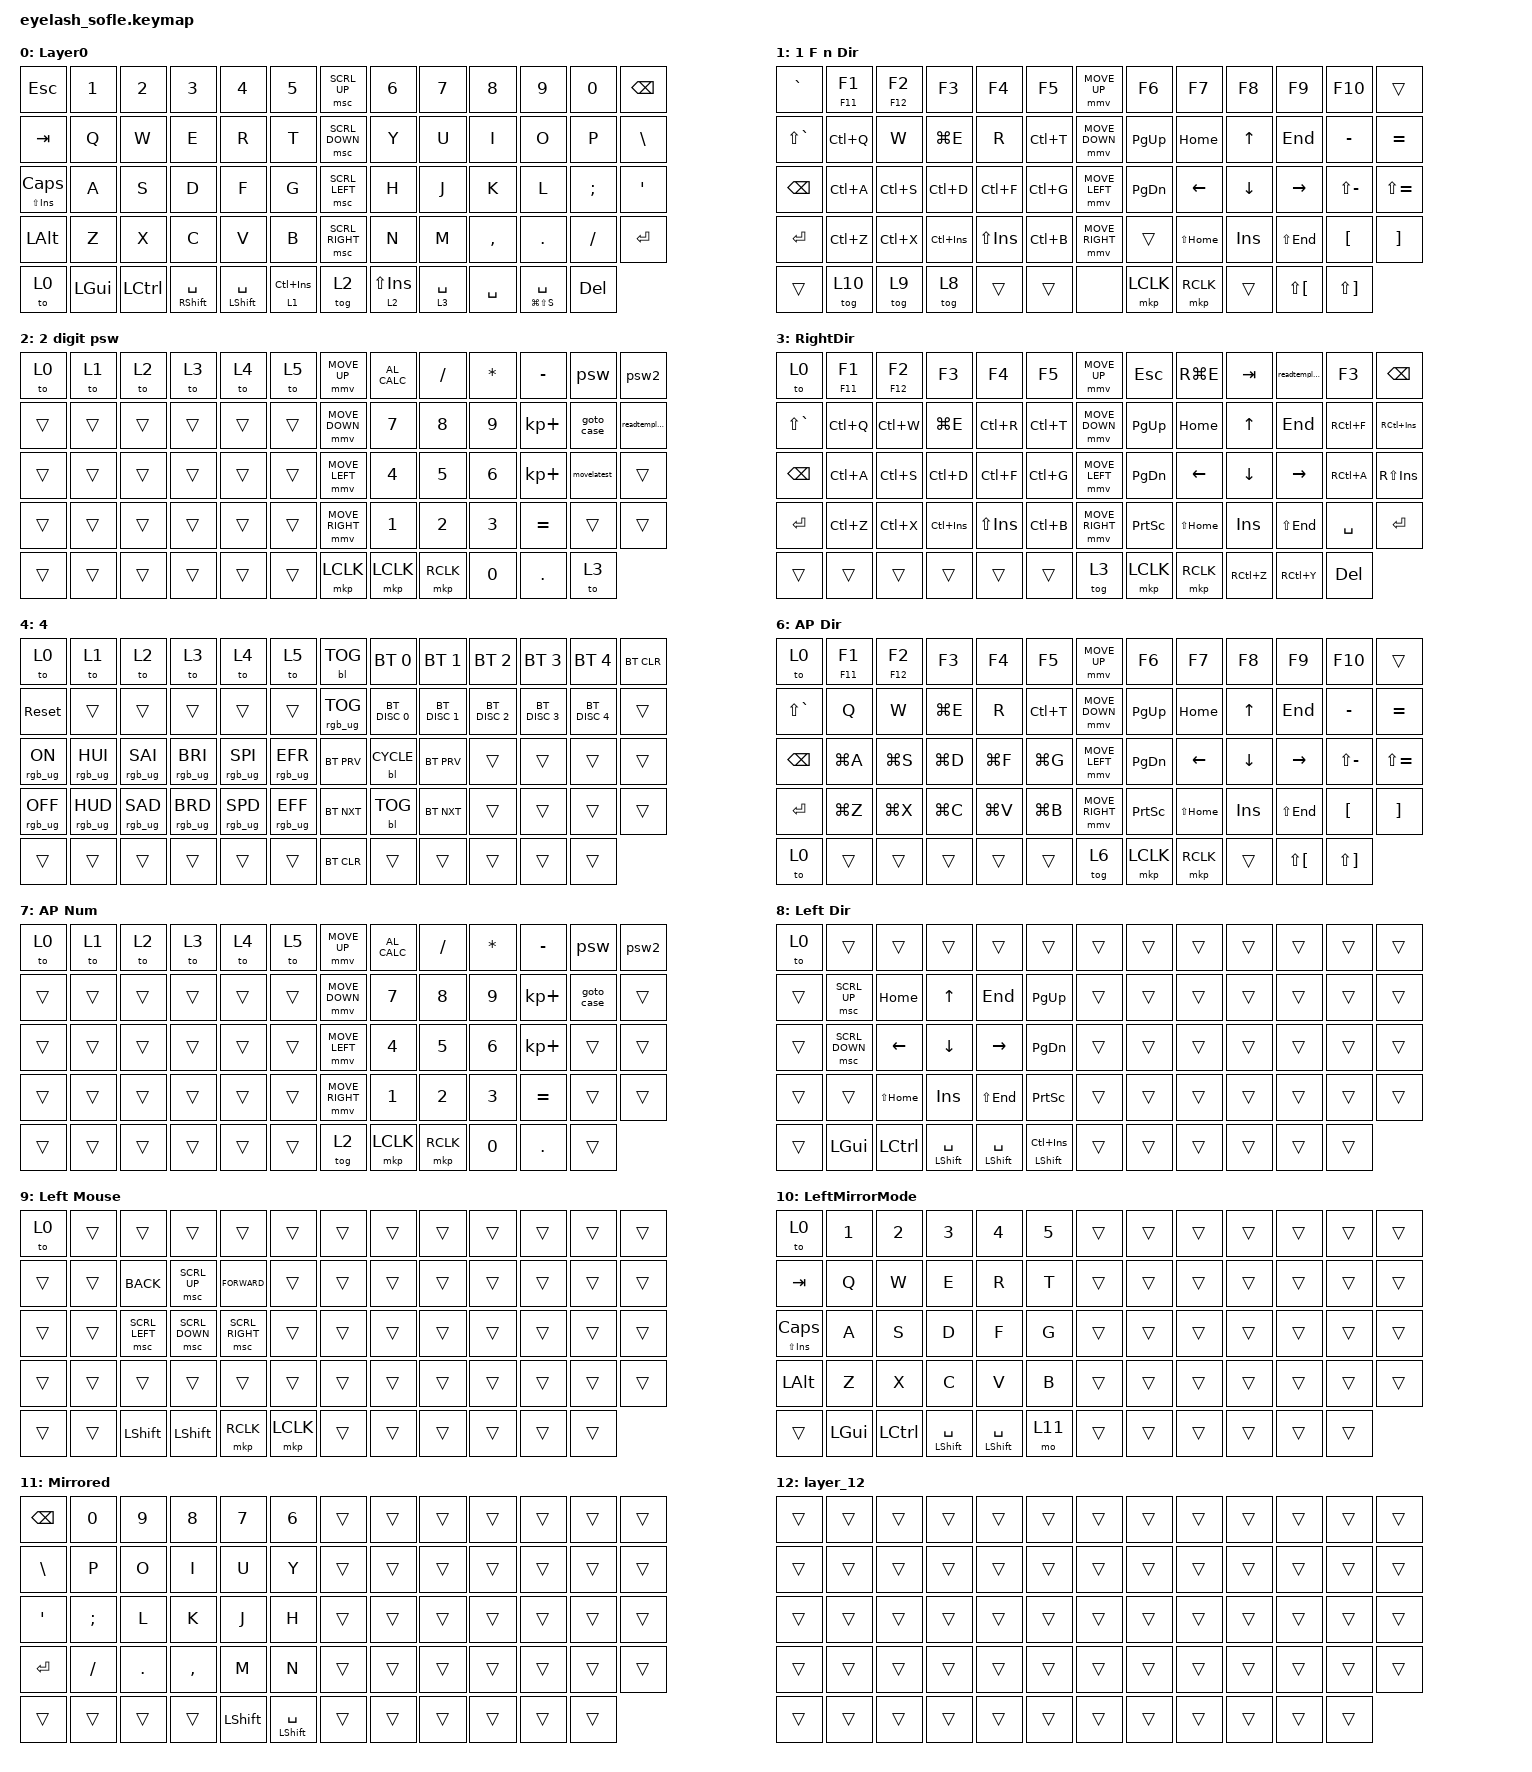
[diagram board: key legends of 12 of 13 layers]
#include <dt-bindings/zmk/mouse.h>
#include <input/processors.dtsi>
#include <behaviors.dtsi>
#include <dt-bindings/zmk/backlight.h>
#include <dt-bindings/zmk/bt.h>
#include <dt-bindings/zmk/keys.h>
#include <dt-bindings/zmk/pointing.h>
#include <dt-bindings/zmk/rgb.h>

/*

   &mmv_input_listener {
       input-processors = <&zip_xy_scaler 2 1>;
   };

   &msc_input_listener {
       input-processors = <&zip_xy_scaler 2 1>;
   };

 */

#define ZMK_MOUSE_DEFAULT_MOVE_VAL 1200  // 600
#define ZMK_MOUSE_DEFAULT_SCRL_VAL 20    // 10

/ {
    behaviors {
        mmv {
            acceleration-exponent = <1>;      // 1
            time-to-max-speed-ms = <900>;    // 40
            delay-ms = <0>;                   // 0
        };

        msc {
            acceleration-exponent = <1>;      // 0
            time-to-max-speed-ms = <400>;      // 500
            delay-ms = <0>;                   //   10
        };
    };

    scroll_encoder: scroll_encoder {
        compatible = "zmk,behavior-sensor-rotate";
        #sensor-binding-cells = <0>;
        bindings = <&kp K_VOLUME_DOWN>, <&kp K_VOLUME_UP>;

        tap-ms = <30>;
        label = "croll_LeftRight";
    };

    rotete_var: rotete_var {
        compatible = "zmk,behavior-sensor-rotate-var";
        label = "ROTETE_VAR";
        #sensor-binding-cells = <2>;
        bindings = <&msc>, <&msc>;

        tap-ms = <30>;
    };

    rotate_up_Down: rotate_up_Down {
        compatible = "zmk,behavior-sensor-rotate";
        label = "ROTATE_UP_DOWN";
        #sensor-binding-cells = <0>;
        bindings = <&msc SCRL_UP>, <&msc SCRL_DOWN>;
    };

    macros {
        goto_case: goto_case {
            compatible = "zmk,behavior-macro";
            #binding-cells = <0>;
            bindings =
                <&macro_press>,
                <&kp LEFT_WIN>,
                <&macro_tap>,
                <&kp R>,
                <&macro_wait_time 80>,
                <&macro_release>,
                <&kp LEFT_WIN>,
                <&macro_tap>,
                <&macro_wait_time 20>,
                <&none &none>,
                <&macro_tap_time 15>,
                <&kp C &kp A &kp S &kp E &kp UNDER &kp G &kp O &kp T &kp O &kp SPACE &kp LS(INSERT) &kp ENTER>;

            label = "GOTO_CASE";
        };

        psw: psw {
            compatible = "zmk,behavior-macro";
            #binding-cells = <0>;
            bindings =
                <&macro_wait_time 30>,
                <&kp LS(A) &kp G &kp A &kp I &kp N &kp A &kp N &kp D &kp LS(A) &kp G &kp A &kp I &kp N &kp I &kp T &kp G &kp O &kp T &kp C &kp H &kp A &kp N &kp G &kp E &kp D &kp N1 &kp AT>;

            label = "PSW";
        };

        psw2: psw2 {
            compatible = "zmk,behavior-macro";
            #binding-cells = <0>;
            bindings =
                <&macro_wait_time 30>,
                <&none &kp LS(A) &kp D &kp M &kp I &kp N &kp I &kp S &kp T &kp R &kp A &kp T &kp O &kp R &kp N1 &kp AT>;

            label = "PSW2";
        };

        movelatest: movelatest {
            compatible = "zmk,behavior-macro";
            #binding-cells = <0>;
            bindings =
                <&macro_press>,
                <&kp LEFT_WIN>,
                <&macro_tap>,
                <&kp R>,
                <&macro_wait_time 80>,
                <&macro_release>,
                <&kp LEFT_WIN>,
                <&macro_tap>,
                <&macro_wait_time 20>,
                <&none &none>,
                <&macro_tap_time 15>,
                <&kp C &kp A &kp S &kp E &kp UNDER &kp M &kp O &kp V &kp E &kp L &kp A &kp T &kp E &kp S &kp T &kp DOT &kp B &kp A &kp T &kp SPACE &kp LS(INSERT)>;

            label = "MOVELATEST";
        };

        readtemplate: readtemplate {
            compatible = "zmk,behavior-macro";
            #binding-cells = <0>;
            bindings =
                <&macro_press>,
                <&kp LEFT_WIN>,
                <&macro_tap>,
                <&kp R>,
                <&macro_wait_time 80>,
                <&macro_release>,
                <&kp LEFT_WIN>,
                <&macro_tap>,
                <&macro_wait_time 30>,
                <&none &none>,
                <&macro_tap_time 20>,
                <&kp R &kp SPACE &kp N3 &kp DELETE &kp ENTER>;

            label = "READTEMPLATE";
        };
    };

    keymap {
        compatible = "zmk,keymap";

        Layer0 {
            bindings = <
&kp ESC           &kp N1        &kp N2            &kp N3           &kp N4                &kp N5           &msc SCRL_UP     &kp N6         &kp N7       &kp N8     &kp N9               &kp N0      &kp BACKSPACE
&kp TAB           &kp Q         &kp W             &kp E            &kp R                 &kp T            &msc SCRL_DOWN   &kp Y          &kp U        &kp I      &kp O                &kp P       &kp BSLH
&mt LS(INS) CAPS  &kp A         &kp S             &kp D            &kp F                 &kp G            &msc SCRL_LEFT   &kp H          &kp J        &kp K      &kp L                &kp SEMI    &kp APOS
&kp LEFT_ALT      &kp Z         &kp X             &kp C            &kp V                 &kp B            &msc SCRL_RIGHT  &kp N          &kp M        &kp COMMA  &kp DOT              &kp FSLH    &kp ENTER
&to 0             &kp LEFT_GUI  &kp LEFT_CONTROL  &mt RSHFT SPACE  &mt LEFT_SHIFT SPACE  &lt 1 LC(INS)    &tog 2           &lt 2 LS(INS)  &lt 3 SPACE  &kp SPACE  &mt LG(LS(S)) SPACE  &kp DELETE
            >;

            sensor-bindings = <&inc_dec_kp C_VOLUME_UP C_VOLUME_DOWN>;
            display-name = "Layer0";
        };

        layer_1 {
            bindings = <
&kp GRAVE      &mt F11 F1  &mt F12 F2  &kp F3       &kp F4       &kp F5       &mmv MOVE_UP     &kp F6         &kp F7        &kp F8    &kp F9                &kp F10                &trans
&kp LS(GRAVE)  &kp LC(Q)   &kp W       &kp LG(E)    &kp R        &kp LC(T)    &mmv MOVE_DOWN   &kp PAGE_UP    &kp HOME      &kp UP    &kp END               &kp MINUS              &kp EQUAL
&kp BSPC       &kp LC(A)   &kp LC(S)   &kp LC(D)    &kp LC(F)    &kp LC(G)    &mmv MOVE_LEFT   &kp PAGE_DOWN  &kp LEFT      &kp DOWN  &kp RIGHT             &kp LS(MINUS)          &kp LS(EQUAL)
&kp ENTER      &kp LC(Z)   &kp LC(X)   &kp LC(INS)  &kp LS(INS)  &kp LC(B)    &mmv MOVE_RIGHT  &trans         &kp LS(HOME)  &kp INS   &kp LS(END)           &kp LEFT_BRACKET       &kp RIGHT_BRACKET
&trans         &tog 10     &tog 9      &tog 8       &trans       &trans       &none            &mkp LCLK      &mkp RCLK     &trans    &kp LS(LEFT_BRACKET)  &kp LS(RIGHT_BRACKET)
            >;

            label = "1 F n Dir ";
            sensor-bindings = <&inc_dec_kp C_BRIGHTNESS_INC C_BRIGHTNESS_DEC>;
        };

        layer_2 {
            bindings = <
&to 0   &to 1   &to 2   &to 3   &to 4   &to 5     &mmv MOVE_UP     &kp C_AL_CALC  &kp FSLH   &kp ASTRK  &kp MINUS    &psw         &psw2
&trans  &trans  &trans  &trans  &trans  &trans    &mmv MOVE_DOWN   &kp N7         &kp N8     &kp N9     &kp KP_PLUS  &goto_case   &readtemplate
&trans  &trans  &trans  &trans  &trans  &trans    &mmv MOVE_LEFT   &kp N4         &kp N5     &kp N6     &kp KP_PLUS  &movelatest  &trans
&trans  &trans  &trans  &trans  &trans  &trans    &mmv MOVE_RIGHT  &kp N1         &kp N2     &kp N3     &kp EQUAL    &trans       &trans
&trans  &trans  &trans  &trans  &trans  &trans    &mkp LCLK        &mkp LCLK      &mkp RCLK  &kp N0     &kp PERIOD   &to 3
            >;

            label = "2 digit psw";
        };

        layer_3 {
            bindings = <
&to 0          &mt F11 F1  &mt F12 F2  &kp F3       &kp F4       &kp F5       &mmv MOVE_UP     &kp ESCAPE       &kp RG(E)     &kp TAB    &readtemplate  &kp F3      &kp BACKSPACE
&kp LS(GRAVE)  &kp LC(Q)   &kp LC(W)   &kp LG(E)    &kp LC(R)    &kp LC(T)    &mmv MOVE_DOWN   &kp PAGE_UP      &kp HOME      &kp UP     &kp END        &kp RC(F)   &kp RC(INSERT)
&kp BSPC       &kp LC(A)   &kp LC(S)   &kp LC(D)    &kp LC(F)    &kp LC(G)    &mmv MOVE_LEFT   &kp PAGE_DOWN    &kp LEFT      &kp DOWN   &kp RIGHT      &kp RC(A)   &kp RS(INSERT)
&kp ENTER      &kp LC(Z)   &kp LC(X)   &kp LC(INS)  &kp LS(INS)  &kp LC(B)    &mmv MOVE_RIGHT  &kp PRINTSCREEN  &kp LS(HOME)  &kp INS    &kp LS(END)    &kp SPACE   &kp ENTER
&trans         &trans      &trans      &trans       &trans       &trans       &tog 3           &mkp LCLK        &mkp RCLK     &kp RC(Z)  &kp RC(Y)      &kp DELETE
            >;

            label = "RightDir";
        };

        control_4 {
            bindings = <
&to 0            &to 1            &to 2            &to 3            &to 4            &to 5              &bl BL_TOG       &bt BT_SEL 0   &bt BT_SEL 1   &bt BT_SEL 2   &bt BT_SEL 3   &bt BT_SEL 4   &bt BT_CLR
&sys_reset       &trans           &trans           &trans           &trans           &trans             &rgb_ug RGB_TOG  &bt BT_DISC 0  &bt BT_DISC 1  &bt BT_DISC 2  &bt BT_DISC 3  &bt BT_DISC 4  &trans
&rgb_ug RGB_ON   &rgb_ug RGB_HUI  &rgb_ug RGB_SAI  &rgb_ug RGB_BRI  &rgb_ug RGB_SPI  &rgb_ug RGB_EFR    &bt BT_PRV       &bl BL_CYCLE   &bt BT_PRV     &trans         &trans         &trans         &trans
&rgb_ug RGB_OFF  &rgb_ug RGB_HUD  &rgb_ug RGB_SAD  &rgb_ug RGB_BRD  &rgb_ug RGB_SPD  &rgb_ug RGB_EFF    &bt BT_NXT       &bl BL_TOG     &bt BT_NXT     &trans         &trans         &trans         &trans
&trans           &trans           &trans           &trans           &trans           &trans             &bt BT_CLR       &trans         &trans         &trans         &trans         &trans
            >;

            label = "4";
        };

        AP0 {
            display-name = "AP0";
            bindings = <
&kp ESC         &kp N1        &kp N2            &kp N3           &kp N4                &kp N5         &msc SCRL_DOWN   &kp N6       &kp N7       &kp N8               &kp N9                          &kp N0      &kp BACKSPACE
&kp TAB         &kp Q         &kp W             &kp E            &kp R                 &kp T          &msc SCRL_UP     &kp Y        &kp U        &kp I                &kp O                           &kp P       &kp BSLH
&mt LG(V) CAPS  &kp A         &kp S             &kp D            &kp F                 &kp G          &msc SCRL_RIGHT  &kp H        &kp J        &kp K                &kp L                           &kp SEMI    &kp APOS
&kp LEFT_ALT    &kp Z         &kp X             &kp C            &kp V                 &kp B          &msc SCRL_LEFT   &kp N        &kp M        &kp COMMA            &kp DOT                         &kp FSLH    &kp ENTER
&trans          &kp LEFT_GUI  &kp LEFT_CONTROL  &mt RSHFT SPACE  &mt LEFT_SHIFT SPACE  &lt 6 LG(C)    &tog 6           &lt 7 RG(V)  &lt 6 SPACE  &mt LS(SPACE) SPACE  &mt LG(LS(LC(NUMBER_4))) SPACE  &kp DELETE
            >;

            sensor-bindings = <&inc_dec_kp C_VOLUME_UP C_VOL_DN>;
        };

        AP1 {
            label = "AP Dir";
            bindings = <
&to 0          &mt F11 F1  &mt F12 F2  &kp F3     &kp F4     &kp F5       &mmv MOVE_UP     &kp F6           &kp F7        &kp F8    &kp F9                &kp F10                &trans
&kp LS(GRAVE)  &kp Q       &kp W       &kp LG(E)  &kp R      &kp LC(T)    &mmv MOVE_DOWN   &kp PAGE_UP      &kp HOME      &kp UP    &kp END               &kp MINUS              &kp EQUAL
&kp BSPC       &kp LG(A)   &kp LG(S)   &kp LG(D)  &kp LG(F)  &kp LG(G)    &mmv MOVE_LEFT   &kp PAGE_DOWN    &kp LEFT      &kp DOWN  &kp RIGHT             &kp LS(MINUS)          &kp LS(EQUAL)
&kp ENTER      &kp LG(Z)   &kp LG(X)   &kp LG(C)  &kp LG(V)  &kp LG(B)    &mmv MOVE_RIGHT  &kp PRINTSCREEN  &kp LS(HOME)  &kp INS   &kp LS(END)           &kp LEFT_BRACKET       &kp RIGHT_BRACKET
&to 0          &trans      &trans      &trans     &trans     &trans       &tog 6           &mkp LCLK        &mkp RCLK     &trans    &kp LS(LEFT_BRACKET)  &kp LS(RIGHT_BRACKET)
            >;
        };

        APNum {
            label = "AP Num";
            bindings = <
&to 0   &to 1   &to 2   &to 3   &to 4   &to 5     &mmv MOVE_UP     &kp C_AL_CALC  &kp FSLH   &kp ASTRK  &kp MINUS    &psw        &psw2
&trans  &trans  &trans  &trans  &trans  &trans    &mmv MOVE_DOWN   &kp N7         &kp N8     &kp N9     &kp KP_PLUS  &goto_case  &trans
&trans  &trans  &trans  &trans  &trans  &trans    &mmv MOVE_LEFT   &kp N4         &kp N5     &kp N6     &kp KP_PLUS  &trans      &trans
&trans  &trans  &trans  &trans  &trans  &trans    &mmv MOVE_RIGHT  &kp N1         &kp N2     &kp N3     &kp EQUAL    &trans      &trans
&trans  &trans  &trans  &trans  &trans  &trans    &tog 2           &mkp LCLK      &mkp RCLK  &kp N0     &kp PERIOD   &trans
            >;

            sensor-bindings = <&rotate_up_Down>;
        };

        LeftDir {
            bindings = <
&to 0   &trans          &trans            &trans                &trans                &trans                       &trans  &trans  &trans  &trans  &trans  &trans  &trans
&trans  &msc SCRL_UP    &kp HOME          &kp UP                &kp END               &kp PG_UP                    &trans  &trans  &trans  &trans  &trans  &trans  &trans
&trans  &msc SCRL_DOWN  &kp LEFT          &kp DOWN              &kp RIGHT             &kp PG_DN                    &trans  &trans  &trans  &trans  &trans  &trans  &trans
&trans  &trans          &kp LS(HOME)      &kp INS               &kp LS(END)           &kp PRINTSCREEN              &trans  &trans  &trans  &trans  &trans  &trans  &trans
&trans  &kp LEFT_GUI    &kp LEFT_CONTROL  &mt LEFT_SHIFT SPACE  &mt LEFT_SHIFT SPACE  &mt LEFT_SHIFT LC(INSERT)    &trans  &trans  &trans  &trans  &trans  &trans
            >;

            label = "Left Dir";
        };

        LeftMouse {
            bindings = <
&to 0   &trans  &trans          &trans          &trans           &trans       &trans  &trans  &trans  &trans  &trans  &trans  &trans
&trans  &trans  &kp K_BACK      &msc SCRL_UP    &kp K_FORWARD    &trans       &trans  &trans  &trans  &trans  &trans  &trans  &trans
&trans  &trans  &msc SCRL_LEFT  &msc SCRL_DOWN  &msc SCRL_RIGHT  &trans       &trans  &trans  &trans  &trans  &trans  &trans  &trans
&trans  &trans  &trans          &trans          &trans           &trans       &trans  &trans  &trans  &trans  &trans  &trans  &trans
&trans  &trans  &kp LEFT_SHIFT  &kp LEFT_SHIFT  &mkp RCLK        &mkp LCLK    &trans  &trans  &trans  &trans  &trans  &trans
            >;

            label = "Left Mouse";
        };

        LeftMirrorMode {
            bindings = <
&to 0                    &kp N1        &kp N2            &kp N3                &kp N4                &kp N5    &trans  &trans  &trans  &trans  &trans  &trans  &trans
&kp TAB                  &kp Q         &kp W             &kp E                 &kp R                 &kp T     &trans  &trans  &trans  &trans  &trans  &trans  &trans
&mt LS(INSERT) CAPSLOCK  &kp A         &kp S             &kp D                 &kp F                 &kp G     &trans  &trans  &trans  &trans  &trans  &trans  &trans
&kp LEFT_ALT             &kp Z         &kp X             &kp C                 &kp V                 &kp B     &trans  &trans  &trans  &trans  &trans  &trans  &trans
&trans                   &kp LEFT_GUI  &kp LEFT_CONTROL  &mt LEFT_SHIFT SPACE  &mt LEFT_SHIFT SPACE  &mo 11    &trans  &trans  &trans  &trans  &trans  &trans
            >;

            label = "LeftMirrorMode";
        };

        Mirrored {
            bindings = <
&kp BACKSPACE  &kp N0    &kp N9   &kp N8     &kp N7          &kp N6                  &trans  &trans  &trans  &trans  &trans  &trans  &trans
&kp BSLH       &kp P     &kp O    &kp I      &kp U           &kp Y                   &trans  &trans  &trans  &trans  &trans  &trans  &trans
&kp SQT        &kp SEMI  &kp L    &kp K      &kp J           &kp H                   &trans  &trans  &trans  &trans  &trans  &trans  &trans
&kp RET        &kp FSLH  &kp DOT  &kp COMMA  &kp M           &kp N                   &trans  &trans  &trans  &trans  &trans  &trans  &trans
&trans         &trans    &trans   &trans     &kp LEFT_SHIFT  &mt LEFT_SHIFT SPACE    &trans  &trans  &trans  &trans  &trans  &trans
            >;

            label = "Mirrored";
        };

        layer_12 {
            bindings = <
&trans  &trans  &trans  &trans  &trans  &trans    &trans  &trans  &trans  &trans  &trans  &trans  &trans
&trans  &trans  &trans  &trans  &trans  &trans    &trans  &trans  &trans  &trans  &trans  &trans  &trans
&trans  &trans  &trans  &trans  &trans  &trans    &trans  &trans  &trans  &trans  &trans  &trans  &trans
&trans  &trans  &trans  &trans  &trans  &trans    &trans  &trans  &trans  &trans  &trans  &trans  &trans
&trans  &trans  &trans  &trans  &trans  &trans    &trans  &trans  &trans  &trans  &trans  &trans
            >;
        };
    };
};
